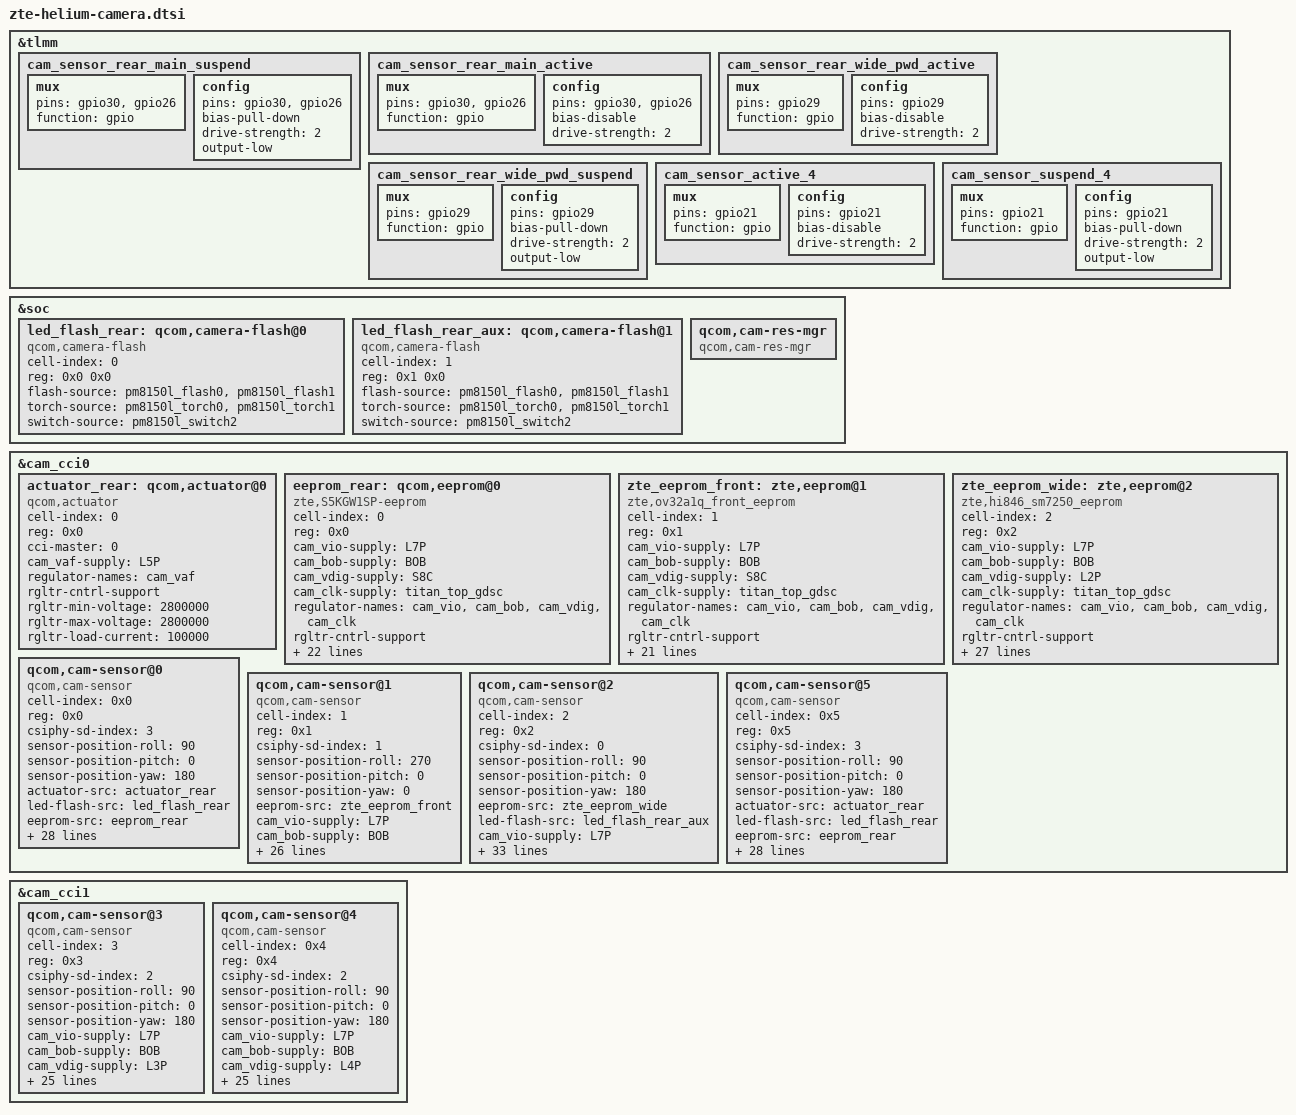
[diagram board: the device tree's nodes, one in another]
&tlmm {
	cam_sensor_rear_main_suspend: cam_sensor_rear_main_suspend {
		mux {
			pins = "gpio30", "gpio26";
			function = "gpio";
		};

		config {
			pins = "gpio30", "gpio26";
			bias-pull-down;
			drive-strength = <2>;
			output-low;
		};
	};

	cam_sensor_rear_main_active: cam_sensor_rear_main_active {
		mux {
			pins = "gpio30", "gpio26";
			function = "gpio";
		};

		config {
			pins = "gpio30", "gpio26";
			bias-disable;
			drive-strength = <2>;
		};
	};

	cam_sensor_rear_wide_pwd_active: cam_sensor_rear_wide_pwd_active {
		mux {
			pins = "gpio29";
			function = "gpio";
		};

		config {
			pins = "gpio29";
			bias-disable;
			drive-strength = <2>;
		};
	};

	cam_sensor_rear_wide_pwd_suspend: cam_sensor_rear_wide_pwd_suspend {
		mux {
			pins = "gpio29";
			function = "gpio";
		};

		config {
			pins = "gpio29";
			bias-pull-down;
			drive-strength = <2>;
			output-low;
		};
	};

	cam_sensor_active_4: cam_sensor_active_4 {
		mux {
			pins = "gpio21";
			function = "gpio";
		};

		config {
			pins = "gpio21";
			bias-disable;
			drive-strength = <2>;
		};
	};

	cam_sensor_suspend_4: cam_sensor_suspend_4 {
		mux {
			pins = "gpio21";
			function = "gpio";
		};

		config {
			pins = "gpio21";
			bias-pull-down;
			drive-strength = <2>;
			output-low;
		};
	};
};

&soc {
	led_flash_rear: qcom,camera-flash@0 {
		cell-index = <0>;
		reg = <0x0 0x0>;
		compatible = "qcom,camera-flash";
		flash-source = <&pm8150l_flash0 &pm8150l_flash1>;
		torch-source = <&pm8150l_torch0 &pm8150l_torch1>;
		switch-source = <&pm8150l_switch2>;
	};

	led_flash_rear_aux: qcom,camera-flash@1 {
		cell-index = <1>;
		reg = <0x1 0x0>;
		compatible = "qcom,camera-flash";
		flash-source = <&pm8150l_flash0 &pm8150l_flash1>;
		torch-source = <&pm8150l_torch0 &pm8150l_torch1>;
		switch-source = <&pm8150l_switch2>;
	};

	qcom,cam-res-mgr {
		compatible = "qcom,cam-res-mgr";
		status = "ok";
	};
};

&cam_cci0 {
	actuator_rear: qcom,actuator@0 {
		cell-index = <0>;
		reg = <0x0>;
		compatible = "qcom,actuator";
		cci-master = <0>;
		cam_vaf-supply = <&L5P>;
		regulator-names = "cam_vaf";
		rgltr-cntrl-support;
		rgltr-min-voltage = <2800000>;
		rgltr-max-voltage = <2800000>;
		rgltr-load-current = <100000>;
		status = "ok";
	};

	eeprom_rear: qcom,eeprom@0 {
		cell-index = <0>;
		reg = <0x0>;
		compatible = "zte,S5KGW1SP-eeprom";
		cam_vio-supply = <&L7P>;
		cam_bob-supply = <&BOB>;
		cam_vdig-supply = <&S8C>;
		cam_clk-supply = <&titan_top_gdsc>;
		regulator-names = "cam_vio", "cam_bob", "cam_vdig", "cam_clk";
		rgltr-cntrl-support;
		pwm-switch;
		rgltr-min-voltage = <1800000 2800000 1050000 0>;
		rgltr-max-voltage = <1800000 2800000 1050000 0>;
		rgltr-load-current = <0 80000 1200000 0>;
		gpio-no-mux = <0>;
		pinctrl-names = "cam_default", "cam_suspend";
		pinctrl-0 = <&cam_sensor_mclk0_active &cam_sensor_rear_main_active>;
		pinctrl-1 = <&cam_sensor_mclk0_suspend &cam_sensor_rear_main_suspend>;
		gpios = <&tlmm 13 0>, <&tlmm 30 0>, <&tlmm 26 0>;
		gpio-reset = <1>;
		gpio-custom1 = <2>;
		gpio-req-tbl-num = <0 1 2>;
		gpio-req-tbl-flags = <1 0 0>;
		gpio-req-tbl-label = "CAMIF_MCLK0", "CAM_RESET0", "CAM_VANA0";
		sensor-position = <0>;
		sensor-mode = <0>;
		cci-master = <0>;
		status = "ok";
		clocks = <&camcc CAM_CC_MCLK0_CLK>;
		clock-names = "cam_clk";
		clock-cntl-level = "turbo";
		clock-rates = <24000000>;
	};

	zte_eeprom_front: zte,eeprom@1 {
		cell-index = <1>;
		reg = <0x1>;
		compatible = "zte,ov32a1q_front_eeprom";
		cam_vio-supply = <&L7P>;
		cam_bob-supply = <&BOB>;
		cam_vdig-supply = <&S8C>;
		cam_clk-supply = <&titan_top_gdsc>;
		regulator-names = "cam_vio", "cam_bob", "cam_vdig", "cam_clk";
		rgltr-cntrl-support;
		pwm-switch;
		rgltr-min-voltage = <1800000 2800000 1050000 0>;
		rgltr-max-voltage = <1800000 2800000 1050000 0>;
		rgltr-load-current = <0 80000 105000 0>;
		gpio-no-mux = <0>;
		pinctrl-names = "cam_default", "cam_suspend";
		pinctrl-0 = <&cam_sensor_mclk2_active &cam_sensor_active_front>;
		pinctrl-1 = <&cam_sensor_mclk2_suspend &cam_sensor_suspend_front>;
		gpios = <&tlmm 15 0>, <&tlmm 32 0>, <&tlmm 22 0>;
		gpio-reset = <1>;
		gpio-custom1 = <2>;
		gpio-req-tbl-num = <0 1 2>;
		gpio-req-tbl-flags = <1 0 0>;
		gpio-req-tbl-label = "CAMIF_MCLK2", "CAM_RESET2", "CAM_VANA2";
		sensor-mode = <0>;
		cci-master = <1>;
		status = "ok";
		clocks = <&camcc CAM_CC_MCLK2_CLK>;
		clock-names = "cam_clk";
		clock-cntl-level = "turbo";
		clock-rates = <24000000>;
	};

	zte_eeprom_wide: zte,eeprom@2 {
		cell-index = <2>;
		reg = <0x2>;
		compatible = "zte,hi846_sm7250_eeprom";
		cam_vio-supply = <&L7P>;
		cam_bob-supply = <&BOB>;
		cam_vdig-supply = <&L2P>;
		cam_clk-supply = <&titan_top_gdsc>;
		regulator-names = "cam_vio", "cam_bob", "cam_vdig", "cam_clk";
		rgltr-cntrl-support;
		pwm-switch;
		rgltr-min-voltage = <1800000 2800000 1200000 0>;
		rgltr-max-voltage = <1800000 2800000 1200000 0>;
		rgltr-load-current = <0 80000 120000 0>;
		gpio-no-mux = <0>;
		pinctrl-names = "cam_default", "cam_suspend";
		pinctrl-0 = <&cam_sensor_mclk1_active &gpio4_dig_out_enable &cam_sensor_rear_wide_pwd_active &gpio6_dig_out_enable>;
		pinctrl-1 = <&cam_sensor_mclk1_suspend &gpio4_dig_out_disable &cam_sensor_rear_wide_pwd_suspend &gpio6_dig_out_disable>;
		gpios = <&tlmm 14 0>, <&pm8150l_gpios 4 0>, <&tlmm 29 0>, <&pm8150_gpios 6 0>;
		gpio-reset = <1>;
		gpio-custom2 = <2>;
		gpio-custom1 = <3>;
		gpio-req-tbl-num = <0 1 2 3>;
		gpio-req-tbl-flags = <1 0 0 0>;
		gpio-req-tbl-label = "CAMIF_MCLK1", "CAM_RESET1", "CAM_PWD1", "CAM_VANA1";
		sensor-mode = <0>;
		cci-master = <1>;
		clocks = <&camcc CAM_CC_MCLK1_CLK>;
		clock-names = "cam_clk";
		clock-cntl-level = "turbo";
		status = "ok";
		clock-rates = <24000000>;
	};

	qcom,cam-sensor@0 {
		cell-index = <0x0>;
		compatible = "qcom,cam-sensor";
		reg = <0x0>;
		csiphy-sd-index = <3>;
		sensor-position-roll = <90>;
		sensor-position-pitch = <0>;
		sensor-position-yaw = <180>;
		actuator-src = <&actuator_rear>;
		led-flash-src = <&led_flash_rear>;
		eeprom-src = <&eeprom_rear>;
		cam_vio-supply = <&L7P>;
		cam_bob-supply = <&BOB>;
		cam_vdig-supply = <&S8C>;
		cam_clk-supply = <&titan_top_gdsc>;
		regulator-names = "cam_vio", "cam_bob", "cam_vdig", "cam_clk";
		rgltr-cntrl-support;
		pwm-switch;
		rgltr-min-voltage = <1800000 2800000 1050000 0>;
		rgltr-max-voltage = <1800000 2800000 1050000 0>;
		rgltr-load-current = <0 80000 1200000 0>;
		gpio-no-mux = <0>;
		pinctrl-names = "cam_default", "cam_suspend";
		pinctrl-0 = <&cam_sensor_mclk0_active &cam_sensor_rear_main_active>;
		pinctrl-1 = <&cam_sensor_mclk0_suspend &cam_sensor_rear_main_suspend>;
		gpios = <&tlmm 13 0>, <&tlmm 30 0>, <&tlmm 26 0>;
		gpio-reset = <1>;
		gpio-custom1 = <2>;
		gpio-req-tbl-num = <0 1 2>;
		gpio-req-tbl-flags = <1 0 0>;
		gpio-req-tbl-label = "CAMIF_MCLK0", "CAM_RESET0", "CAM_VANA0";
		sensor-mode = <0>;
		cci-master = <0>;
		status = "ok";
		clocks = <&camcc CAM_CC_MCLK0_CLK>;
		clock-names = "cam_clk";
		clock-cntl-level = "turbo";
		clock-rates = <24000000>;
	};

	qcom,cam-sensor@1 {
		cell-index = <1>;
		compatible = "qcom,cam-sensor";
		reg = <0x1>;
		csiphy-sd-index = <1>;
		sensor-position-roll = <270>;
		sensor-position-pitch = <0>;
		sensor-position-yaw = <0>;
		eeprom-src = <&zte_eeprom_front>;
		cam_vio-supply = <&L7P>;
		cam_bob-supply = <&BOB>;
		cam_vdig-supply = <&S8C>;
		cam_clk-supply = <&titan_top_gdsc>;
		regulator-names = "cam_vio", "cam_bob", "cam_vdig", "cam_clk";
		rgltr-cntrl-support;
		pwm-switch;
		rgltr-min-voltage = <1800000 2800000 1050000 0>;
		rgltr-max-voltage = <1800000 2800000 1050000 0>;
		rgltr-load-current = <0 80000 105000 0>;
		gpio-no-mux = <0>;
		pinctrl-names = "cam_default", "cam_suspend";
		pinctrl-0 = <&cam_sensor_mclk2_active &cam_sensor_active_front>;
		pinctrl-1 = <&cam_sensor_mclk2_suspend &cam_sensor_suspend_front>;
		gpios = <&tlmm 15 0>, <&tlmm 32 0>, <&tlmm 22 0>;
		gpio-reset = <1>;
		gpio-custom1 = <2>;
		gpio-req-tbl-num = <0 1 2>;
		gpio-req-tbl-flags = <1 0 0>;
		gpio-req-tbl-label = "CAMIF_MCLK2", "CAM_RESET2", "CAM_VANA2";
		sensor-mode = <0>;
		cci-master = <1>;
		status = "ok";
		clocks = <&camcc CAM_CC_MCLK2_CLK>;
		clock-names = "cam_clk";
		clock-cntl-level = "turbo";
		clock-rates = <24000000>;
	};

	qcom,cam-sensor@2 {
		cell-index = <2>;
		compatible = "qcom,cam-sensor";
		reg = <0x2>;
		csiphy-sd-index = <0>;
		sensor-position-roll = <90>;
		sensor-position-pitch = <0>;
		sensor-position-yaw = <180>;
		eeprom-src = <&zte_eeprom_wide>;
		led-flash-src = <&led_flash_rear_aux>;
		cam_vio-supply = <&L7P>;
		cam_bob-supply = <&BOB>;
		cam_vdig-supply = <&L2P>;
		cam_clk-supply = <&titan_top_gdsc>;
		regulator-names = "cam_vio", "cam_bob", "cam_vdig", "cam_clk";
		rgltr-cntrl-support;
		pwm-switch;
		rgltr-min-voltage = <1800000 2800000 1200000 0>;
		rgltr-max-voltage = <1800000 2800000 1200000 0>;
		rgltr-load-current = <0 80000 120000 0>;
		gpio-no-mux = <0>;
		pinctrl-names = "cam_default", "cam_suspend";
		pinctrl-0 = <&cam_sensor_mclk1_active &gpio4_dig_out_enable &cam_sensor_rear_wide_pwd_active &gpio6_dig_out_enable>;
		pinctrl-1 = <&cam_sensor_mclk1_suspend &gpio4_dig_out_disable &cam_sensor_rear_wide_pwd_suspend &gpio6_dig_out_disable>;
		gpios = <&tlmm 14 0>, <&pm8150l_gpios 4 0>, <&tlmm 29 0>, <&pm8150_gpios 6 0>;
		gpio-reset = <1>;
		gpio-custom2 = <2>;
		gpio-custom1 = <3>;
		gpio-req-tbl-num = <0 1 2 3>;
		gpio-req-tbl-flags = <1 0 0 0>;
		gpio-req-tbl-label = "CAMIF_MCLK1", "CAM_RESET1", "CAM_PWD1", "CAM_VANA1";
		sensor-mode = <0>;
		cci-master = <1>;
		clocks = <&camcc CAM_CC_MCLK1_CLK>;
		clock-names = "cam_clk";
		clock-cntl-level = "turbo";
		status = "ok";
		clock-rates = <24000000>;
	};

	qcom,cam-sensor@5 {
		cell-index = <0x5>;
		compatible = "qcom,cam-sensor";
		reg = <0x5>;
		csiphy-sd-index = <3>;
		sensor-position-roll = <90>;
		sensor-position-pitch = <0>;
		sensor-position-yaw = <180>;
		actuator-src = <&actuator_rear>;
		led-flash-src = <&led_flash_rear>;
		eeprom-src = <&eeprom_rear>;
		cam_vio-supply = <&L7P>;
		cam_bob-supply = <&BOB>;
		cam_vdig-supply = <&S8C>;
		cam_clk-supply = <&titan_top_gdsc>;
		regulator-names = "cam_vio", "cam_bob", "cam_vdig", "cam_clk";
		rgltr-cntrl-support;
		pwm-switch;
		rgltr-min-voltage = <1800000 2800000 1050000 0>;
		rgltr-max-voltage = <1800000 2800000 1050000 0>;
		rgltr-load-current = <0 80000 1200000 0>;
		gpio-no-mux = <0>;
		pinctrl-names = "cam_default", "cam_suspend";
		pinctrl-0 = <&cam_sensor_mclk0_active &cam_sensor_rear_main_active>;
		pinctrl-1 = <&cam_sensor_mclk0_suspend &cam_sensor_rear_main_suspend>;
		gpios = <&tlmm 13 0>, <&tlmm 30 0>, <&tlmm 26 0>;
		gpio-reset = <1>;
		gpio-custom1 = <2>;
		gpio-req-tbl-num = <0 1 2>;
		gpio-req-tbl-flags = <1 0 0>;
		gpio-req-tbl-label = "CAMIF_MCLK0", "CAM_RESET0", "CAM_VANA0";
		sensor-mode = <0>;
		cci-master = <0>;
		status = "ok";
		clocks = <&camcc CAM_CC_MCLK0_CLK>;
		clock-names = "cam_clk";
		clock-cntl-level = "turbo";
		clock-rates = <24000000>;
	};
};

&cam_cci1 {
	qcom,cam-sensor@3 {
		cell-index = <3>;
		compatible = "qcom,cam-sensor";
		reg = <0x3>;
		csiphy-sd-index = <2>;
		sensor-position-roll = <90>;
		sensor-position-pitch = <0>;
		sensor-position-yaw = <180>;
		cam_vio-supply = <&L7P>;
		cam_bob-supply = <&BOB>;
		cam_vdig-supply = <&L3P>;
		cam_clk-supply = <&titan_top_gdsc>;
		regulator-names = "cam_vio", "cam_bob", "cam_vdig", "cam_clk";
		rgltr-cntrl-support;
		pwm-switch;
		rgltr-min-voltage = <1800000 2800000 1800000 0>;
		rgltr-max-voltage = <1800000 2800000 1800000 0>;
		rgltr-load-current = <0 80000 180000 0>;
		gpio-no-mux = <0>;
		pinctrl-names = "cam_default", "cam_suspend";
		pinctrl-0 = <&cam_sensor_mclk3_active &cam_sensor_active_3 &gpio7_dig_out_enable>;
		pinctrl-1 = <&cam_sensor_mclk3_suspend &cam_sensor_suspend_3 &gpio7_dig_out_disable>;
		gpios = <&tlmm 16 0>, <&tlmm 23 0>, <&pm8150_gpios 7 0>;
		gpio-reset = <1>;
		gpio-custom1 = <2>;
		gpio-req-tbl-num = <0 1 2>;
		gpio-req-tbl-flags = <1 0 0>;
		gpio-req-tbl-label = "CAMIF_MCLK3", "CAM_RESET3", "CAM_VANA3";
		sensor-mode = <0>;
		cci-master = <0>;
		clocks = <&camcc CAM_CC_MCLK3_CLK>;
		clock-names = "cam_clk";
		clock-cntl-level = "turbo";
		status = "ok";
		clock-rates = <24000000>;
	};

	qcom,cam-sensor@4 {
		cell-index = <0x4>;
		compatible = "qcom,cam-sensor";
		reg = <0x4>;
		csiphy-sd-index = <2>;
		sensor-position-roll = <90>;
		sensor-position-pitch = <0>;
		sensor-position-yaw = <180>;
		cam_vio-supply = <&L7P>;
		cam_bob-supply = <&BOB>;
		cam_vdig-supply = <&L4P>;
		cam_clk-supply = <&titan_top_gdsc>;
		regulator-names = "cam_vio", "cam_bob", "cam_vdig", "cam_clk";
		rgltr-cntrl-support;
		pwm-switch;
		rgltr-min-voltage = <1800000 2800000 1800000 0>;
		rgltr-max-voltage = <1800000 2800000 1800000 0>;
		rgltr-load-current = <0 80000 180000 0>;
		gpio-no-mux = <0>;
		pinctrl-names = "cam_default", "cam_suspend";
		pinctrl-0 = <&cam_sensor_mclk4_active &cam_sensor_active_4 &gpio9_dig_out_enable>;
		pinctrl-1 = <&cam_sensor_mclk4_suspend &cam_sensor_suspend_4 &gpio9_dig_out_disable>;
		gpios = <&tlmm 25 0>, <&tlmm 21 0>, <&pm8150_gpios 9 0>;
		gpio-reset = <1>;
		gpio-custom1 = <2>;
		gpio-req-tbl-num = <0 1 2>;
		gpio-req-tbl-flags = <1 0 0>;
		gpio-req-tbl-label = "CAMIF_MCLK4", "CAM_RESET4", "CAM_VANA4";
		sensor-mode = <0>;
		cci-master = <0>;
		clocks = <&camcc CAM_CC_MCLK4_CLK>;
		clock-names = "cam_clk";
		clock-cntl-level = "turbo";
		status = "ok";
		clock-rates = <24000000>;
	};
};
